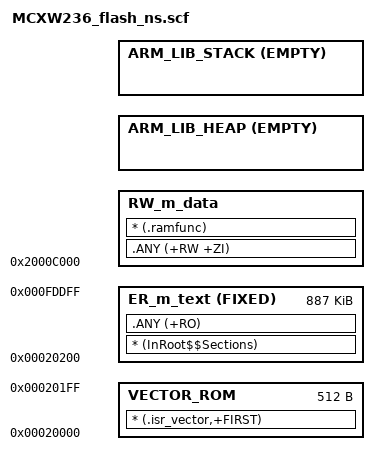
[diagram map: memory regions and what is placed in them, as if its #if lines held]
#!armclang --target=arm-arm-none-eabi -march=armv8-m.main -E -x c
/*
** ###################################################################
**     Processors:          MCXW236AIHNAR
**                          MCXW236AIUKAR
**                          MCXW236BIHNAR
**                          MCXW236BIUKAR
**
**     Compiler:            Keil ARM C/C++ Compiler
**     Reference manual:    MCXW23x User manual Rev. 1.0 - 7 April 2025
**     Version:             rev. 1.0, 2022-03-08
**     Build:               b250819
**
**     Abstract:
**         Linker file for the Keil ARM C/C++ Compiler
**
**     Copyright 2016 Freescale Semiconductor, Inc.
**     Copyright 2016-2025 NXP
**     SPDX-License-Identifier: BSD-3-Clause
**
**     http:                 www.nxp.com
**     mail:                 support@nxp.com
**
** ###################################################################
*/


/* Sizes */
#if (defined(__stack_size__))
  #define Stack_Size                   __stack_size__
#else
  #define Stack_Size                   0x0800
#endif

#if (defined(__heap_size__))
  #define Heap_Size                    __heap_size__
#else
  #define Heap_Size                    0x0400
#endif

#define  m_interrupts_start            0x00020000
#define  m_interrupts_size             0x00000200

#define  m_text_start                  0x00020200
#define  m_text_size                   0x000DDC00

/* NS RAM: SRAM2 (80 KB), NS alias */
#define  m_data_start                  0x2000C000
#define  m_data_size                   0x00014000

LR_m_text m_interrupts_start m_interrupts_size+m_text_size {

  VECTOR_ROM m_interrupts_start m_interrupts_size { ; load address = execution address
    * (.isr_vector,+FIRST)
  }

  ER_m_text m_text_start FIXED m_text_size { ; load address = execution address
    * (InRoot$$Sections)
    .ANY (+RO)
  }

  RW_m_data m_data_start m_data_size-Stack_Size-Heap_Size { ; RW data
    .ANY (+RW +ZI)
    * (.ramfunc)
  }
  ARM_LIB_HEAP +0 EMPTY Heap_Size {    ; Heap region growing up
  }
  ARM_LIB_STACK m_data_start+m_data_size EMPTY -Stack_Size { ; Stack region growing down
  }

  ScatterAssert(ImageLimit(ARM_LIB_STACK) <= 0x20020000); /* Check for NS RAM overflow */
}
